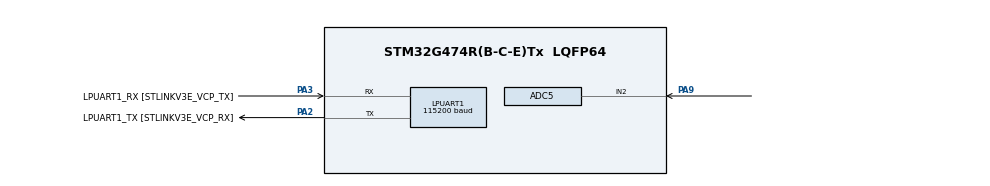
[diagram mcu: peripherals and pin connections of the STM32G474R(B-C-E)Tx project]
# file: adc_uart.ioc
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ADC5.Channel-0\#ChannelRegularConversion=ADC_CHANNEL_2
ADC5.NbrOfConversionFlag=1
ADC5.OffsetNumber-0\#ChannelRegularConversion=ADC_OFFSET_NONE
ADC5.Rank-0\#ChannelRegularConversion=1
ADC5.SamplingTime-0\#ChannelRegularConversion=ADC_SAMPLETIME_2CYCLES_5
LPUART1.BaudRate=115200
Mcu.Family=STM32G4
Mcu.Name=STM32G474R(B-C-E)Tx
Mcu.Package=LQFP64
NVIC.PriorityGroup=NVIC_PRIORITYGROUP_4
PA2.GPIO_Label=LPUART1_TX [STLINKV3E_VCP_RX]
PA2.Mode=Asynchronous
PA2.Signal=LPUART1_TX
PA3.GPIO_Label=LPUART1_RX [STLINKV3E_VCP_TX]
PA3.Mode=Asynchronous
PA3.Signal=LPUART1_RX
PA9.Mode=IN2-Single-Ended
PA9.Signal=ADC5_IN2
ProjectManager.HeapSize=0x200
ProjectManager.StackSize=0x400
ProjectManager.TargetToolchain=STM32CubeIDE
RCC.ADC12Freq_Value=170000000
RCC.ADC345Freq_Value=170000000
RCC.AHBFreq_Value=170000000
RCC.APB1Freq_Value=170000000
RCC.APB1TimFreq_Value=170000000
RCC.APB2Freq_Value=170000000
RCC.APB2TimFreq_Value=170000000
RCC.CortexFreq_Value=170000000
RCC.EXTERNAL_CLOCK_VALUE=12288000
RCC.HCLKFreq_Value=170000000
RCC.HSE_VALUE=24000000
RCC.HSI48_VALUE=48000000
RCC.HSI_VALUE=16000000
RCC.LSE_VALUE=32768
RCC.PLLM=RCC_PLLM_DIV4
RCC.PLLN=85
RCC.RTCClockSelection=RCC_RTCCLKSOURCE_LSE
RCC.SYSCLKFreq_VALUE=170000000
RCC.SYSCLKSource=RCC_SYSCLKSOURCE_PLLCLK
RCC.USBFreq_Value=170000000
RCC.VCOOutputFreq_Value=340000000
VP_SYS_VS_DBSignals.Mode=DisableDeadBatterySignals
board=NUCLEO-G474RE

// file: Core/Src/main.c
/* USER CODE BEGIN Header */
/**
  ******************************************************************************
  * @file           : main.c
  * @brief          : Main program body
  ******************************************************************************
  * @attention
  *
  * Copyright (c) 2026 STMicroelectronics.
  * All rights reserved.
  *
  * This software is licensed under terms that can be found in the LICENSE file
  * in the root directory of this software component.
  * If no LICENSE file comes with this software, it is provided AS-IS.
  *
  ******************************************************************************
  */
/* USER CODE END Header */
#include "main.h"

/* USER CODE BEGIN Includes */
#include <stdio.h>
#include <string.h>
/* USER CODE END Includes */

/* USER CODE BEGIN PV */
uint16_t pot1_raw = 0;       // Τιμή ADC (0 έως 4095)
uint32_t pot1_mv = 0;        // Τάση σε Millivolts (0 έως 3300 mV)
char uart_buf[90];           // Buffer κειμένου
/* USER CODE END PV */

void SystemClock_Config(void);
static void MX_GPIO_Init(void);
static void MX_ADC5_Init(void);
static void MX_LPUART1_UART_Init(void);
/* USER CODE BEGIN PFP */
void LPUART1_SendString(const char *str);
/* USER CODE END PFP */

int main(void)
{

  /* MCU Configuration--------------------------------------------------------*/

  /* Reset of all peripherals, Initializes the Flash interface and the Systick. */
  LL_APB2_GRP1_EnableClock(LL_APB2_GRP1_PERIPH_SYSCFG);
  LL_APB1_GRP1_EnableClock(LL_APB1_GRP1_PERIPH_PWR);

  /* System interrupt init*/
  NVIC_SetPriorityGrouping(NVIC_PRIORITYGROUP_4);

  /** Disable the internal Pull-Up in Dead Battery pins of UCPD peripheral
  */
  LL_PWR_DisableUCPDDeadBattery();

  /* Configure the system clock */
  SystemClock_Config();

  /* Initialize all configured peripherals */
  MX_GPIO_Init();
  MX_ADC5_Init();
  MX_LPUART1_UART_Init();
  /* USER CODE BEGIN 2 */

  /* Βήμα 1: Έλεγχος UART */

  LPUART1_SendString("\r\n=========================================\r\n");
  LPUART1_SendString("1. LPUART1 OK (115200 Baud)\r\n");

  /* Βήμα 2: ADC Calibration */
  LPUART1_SendString("2. Calibrating ADC5...\r\n");
  LL_ADC_StartCalibration(ADC5, LL_ADC_SINGLE_ENDED);
  while (LL_ADC_IsCalibrationOnGoing(ADC5));
  LL_mDelay(5);

  /* Βήμα 3: ADC Enable */
  LPUART1_SendString("3. Enabling ADC5...\r\n");
  LL_ADC_ClearFlag_ADRDY(ADC5);
  LL_ADC_Enable(ADC5);
  while (!LL_ADC_IsActiveFlag_ADRDY(ADC5));

  LPUART1_SendString("4. ADC5 Ready! Starting readings...\r\n");
  LPUART1_SendString("=========================================\r\n\r\n");

  /* USER CODE END 2 */

  /* Infinite loop */
  /* USER CODE BEGIN WHILE */
  while (1)
  {
    /* 1. Εκκίνηση μέτρησης */
    LL_ADC_REG_StartConversion(ADC5);

    /* 2. Αναμονή ολοκλήρωσης */
    while (!LL_ADC_IsActiveFlag_EOC(ADC5));

    /* 3. Ανάγνωση τιμής και καθαρισμός σημαίας */
    pot1_raw = LL_ADC_REG_ReadConversionData12(ADC5);
    LL_ADC_ClearFlag_EOC(ADC5);

    /* 4. Υπολογισμός τάσης σε mV (0 - 3300mV) */
    pot1_mv = ((uint32_t)pot1_raw * 3300U) / 4095U;

    /* 5. Μορφοποίηση με ακεραίους (Volt.milliVolt) */
    snprintf(uart_buf, sizeof(uart_buf),
             "POT1 (ADC5_IN2) -> Raw: %4u | Voltage: %lu.%03lu V\r\n",
             pot1_raw, (pot1_mv / 1000U), (pot1_mv % 1000U));

    /* 6. Αποστολή στο PuTTY */
    LPUART1_SendString(uart_buf);

    /* 7. Καθυστέρηση */
    LL_mDelay(200);

    /* USER CODE END WHILE */

  }
}

void SystemClock_Config(void)
{
  LL_FLASH_SetLatency(LL_FLASH_LATENCY_4);
  while(LL_FLASH_GetLatency() != LL_FLASH_LATENCY_4)
  {
  }
  LL_PWR_EnableRange1BoostMode();
  LL_RCC_HSI_Enable();
   /* Wait till HSI is ready */
  while(LL_RCC_HSI_IsReady() != 1)
  {
  }

  LL_RCC_HSI_SetCalibTrimming(64);
  LL_RCC_PLL_ConfigDomain_SYS(LL_RCC_PLLSOURCE_HSI, LL_RCC_PLLM_DIV_4, 85, LL_RCC_PLLR_DIV_2);
  LL_RCC_PLL_EnableDomain_SYS();
  LL_RCC_PLL_Enable();
   /* Wait till PLL is ready */
  while(LL_RCC_PLL_IsReady() != 1)
  {
  }

  LL_RCC_SetSysClkSource(LL_RCC_SYS_CLKSOURCE_PLL);
  LL_RCC_SetAHBPrescaler(LL_RCC_SYSCLK_DIV_2);
   /* Wait till System clock is ready */
  while(LL_RCC_GetSysClkSource() != LL_RCC_SYS_CLKSOURCE_STATUS_PLL)
  {
  }

  /* Insure 1us transition state at intermediate medium speed clock*/
  for (__IO uint32_t i = (170 >> 1); i !=0; i--);

  /* Set AHB prescaler*/
  LL_RCC_SetAHBPrescaler(LL_RCC_SYSCLK_DIV_1);
  LL_RCC_SetAPB1Prescaler(LL_RCC_APB1_DIV_1);
  LL_RCC_SetAPB2Prescaler(LL_RCC_APB2_DIV_1);

  LL_Init1msTick(170000000);

  LL_SetSystemCoreClock(170000000);
}

static void MX_ADC5_Init(void)
{

  LL_ADC_InitTypeDef ADC_InitStruct = {0};
  LL_ADC_REG_InitTypeDef ADC_REG_InitStruct = {0};

  LL_GPIO_InitTypeDef GPIO_InitStruct = {0};

  LL_RCC_SetADCClockSource(LL_RCC_ADC345_CLKSOURCE_SYSCLK);

  /* Peripheral clock enable */
  LL_AHB2_GRP1_EnableClock(LL_AHB2_GRP1_PERIPH_ADC345);

  LL_AHB2_GRP1_EnableClock(LL_AHB2_GRP1_PERIPH_GPIOA);
  /**ADC5 GPIO Configuration
  PA9   ------> ADC5_IN2
  */
  GPIO_InitStruct.Pin = LL_GPIO_PIN_9;
  GPIO_InitStruct.Mode = LL_GPIO_MODE_ANALOG;
  GPIO_InitStruct.Pull = LL_GPIO_PULL_NO;
  LL_GPIO_Init(GPIOA, &GPIO_InitStruct);

  /** Common config
  */
  ADC_InitStruct.Resolution = LL_ADC_RESOLUTION_12B;
  ADC_InitStruct.DataAlignment = LL_ADC_DATA_ALIGN_RIGHT;
  ADC_InitStruct.LowPowerMode = LL_ADC_LP_MODE_NONE;
  LL_ADC_Init(ADC5, &ADC_InitStruct);
  ADC_REG_InitStruct.TriggerSource = LL_ADC_REG_TRIG_SOFTWARE;
  ADC_REG_InitStruct.SequencerLength = LL_ADC_REG_SEQ_SCAN_DISABLE;
  ADC_REG_InitStruct.SequencerDiscont = LL_ADC_REG_SEQ_DISCONT_DISABLE;
  ADC_REG_InitStruct.ContinuousMode = LL_ADC_REG_CONV_SINGLE;
  ADC_REG_InitStruct.DMATransfer = LL_ADC_REG_DMA_TRANSFER_NONE;
  ADC_REG_InitStruct.Overrun = LL_ADC_REG_OVR_DATA_PRESERVED;
  LL_ADC_REG_Init(ADC5, &ADC_REG_InitStruct);
  LL_ADC_SetGainCompensation(ADC5, 0);
  LL_ADC_SetOverSamplingScope(ADC5, LL_ADC_OVS_DISABLE);
  LL_ADC_SetCommonClock(__LL_ADC_COMMON_INSTANCE(ADC5), LL_ADC_CLOCK_SYNC_PCLK_DIV4);

  /* Disable ADC deep power down (enabled by default after reset state) */
  LL_ADC_DisableDeepPowerDown(ADC5);
  /* Enable ADC internal voltage regulator */
  LL_ADC_EnableInternalRegulator(ADC5);
  /* Delay for ADC internal voltage regulator stabilization. */
  /* Compute number of CPU cycles to wait for, from delay in us. */
  /* Note: Variable divided by 2 to compensate partially */
  /* CPU processing cycles (depends on compilation optimization). */
  /* Note: If system core clock frequency is below 200kHz, wait time */
  /* is only a few CPU processing cycles. */
  uint32_t wait_loop_index;
  wait_loop_index = ((LL_ADC_DELAY_INTERNAL_REGUL_STAB_US * (SystemCoreClock / (100000 * 2))) / 10);
  while(wait_loop_index != 0)
  {
    wait_loop_index--;
  }

  /** Configure Regular Channel
  */
  LL_ADC_REG_SetSequencerRanks(ADC5, LL_ADC_REG_RANK_1, LL_ADC_CHANNEL_2);
  LL_ADC_SetChannelSamplingTime(ADC5, LL_ADC_CHANNEL_2, LL_ADC_SAMPLINGTIME_2CYCLES_5);
  LL_ADC_SetChannelSingleDiff(ADC5, LL_ADC_CHANNEL_2, LL_ADC_SINGLE_ENDED);

}

static void MX_LPUART1_UART_Init(void)
{

  LL_LPUART_InitTypeDef LPUART_InitStruct = {0};

  LL_GPIO_InitTypeDef GPIO_InitStruct = {0};

  LL_RCC_SetLPUARTClockSource(LL_RCC_LPUART1_CLKSOURCE_PCLK1);

  /* Peripheral clock enable */
  LL_APB1_GRP2_EnableClock(LL_APB1_GRP2_PERIPH_LPUART1);

  LL_AHB2_GRP1_EnableClock(LL_AHB2_GRP1_PERIPH_GPIOA);
  /**LPUART1 GPIO Configuration
  PA2   ------> LPUART1_TX
  PA3   ------> LPUART1_RX
  */
  GPIO_InitStruct.Pin = LPUART1_TX_Pin;
  GPIO_InitStruct.Mode = LL_GPIO_MODE_ALTERNATE;
  GPIO_InitStruct.Speed = LL_GPIO_SPEED_FREQ_LOW;
  GPIO_InitStruct.OutputType = LL_GPIO_OUTPUT_PUSHPULL;
  GPIO_InitStruct.Pull = LL_GPIO_PULL_NO;
  GPIO_InitStruct.Alternate = LL_GPIO_AF_12;
  LL_GPIO_Init(LPUART1_TX_GPIO_Port, &GPIO_InitStruct);

  GPIO_InitStruct.Pin = LPUART1_RX_Pin;
  GPIO_InitStruct.Mode = LL_GPIO_MODE_ALTERNATE;
  GPIO_InitStruct.Speed = LL_GPIO_SPEED_FREQ_LOW;
  GPIO_InitStruct.OutputType = LL_GPIO_OUTPUT_PUSHPULL;
  GPIO_InitStruct.Pull = LL_GPIO_PULL_NO;
  GPIO_InitStruct.Alternate = LL_GPIO_AF_12;
  LL_GPIO_Init(LPUART1_RX_GPIO_Port, &GPIO_InitStruct);

  LPUART_InitStruct.PrescalerValue = LL_LPUART_PRESCALER_DIV1;
  LPUART_InitStruct.BaudRate = 115200;
  LPUART_InitStruct.DataWidth = LL_LPUART_DATAWIDTH_8B;
  LPUART_InitStruct.StopBits = LL_LPUART_STOPBITS_1;
  LPUART_InitStruct.Parity = LL_LPUART_PARITY_NONE;
  LPUART_InitStruct.TransferDirection = LL_LPUART_DIRECTION_TX_RX;
  LPUART_InitStruct.HardwareFlowControl = LL_LPUART_HWCONTROL_NONE;
  LL_LPUART_Init(LPUART1, &LPUART_InitStruct);
  LL_LPUART_SetTXFIFOThreshold(LPUART1, LL_LPUART_FIFOTHRESHOLD_1_8);
  LL_LPUART_SetRXFIFOThreshold(LPUART1, LL_LPUART_FIFOTHRESHOLD_1_8);
  LL_LPUART_DisableFIFO(LPUART1);

  LL_LPUART_Enable(LPUART1);

  /* Polling LPUART1 initialisation */
  while((!(LL_LPUART_IsActiveFlag_TEACK(LPUART1))) || (!(LL_LPUART_IsActiveFlag_REACK(LPUART1))))
  {
  }

}

static void MX_GPIO_Init(void)
{

  /* GPIO Ports Clock Enable */
  LL_AHB2_GRP1_EnableClock(LL_AHB2_GRP1_PERIPH_GPIOA);

}

/* USER CODE BEGIN 4 */
void LPUART1_SendString(const char *str)
{
    while (*str)
    {
        /* Αναμονή μέχρι να αδειάσει το TX buffer */
        while (!LL_LPUART_IsActiveFlag_TXE(LPUART1));

        /* Αποστολή ενός χαρακτήρα */
        LL_LPUART_TransmitData8(LPUART1, (uint8_t)(*str++));
    }
    /* Αναμονή μέχρι να ολοκληρωθεί πλήρως η μετάδοση */
    while (!LL_LPUART_IsActiveFlag_TC(LPUART1));
}
/* USER CODE END 4 */

void Error_Handler(void)
{
  __disable_irq();
  while (1)
  {
  }
}
